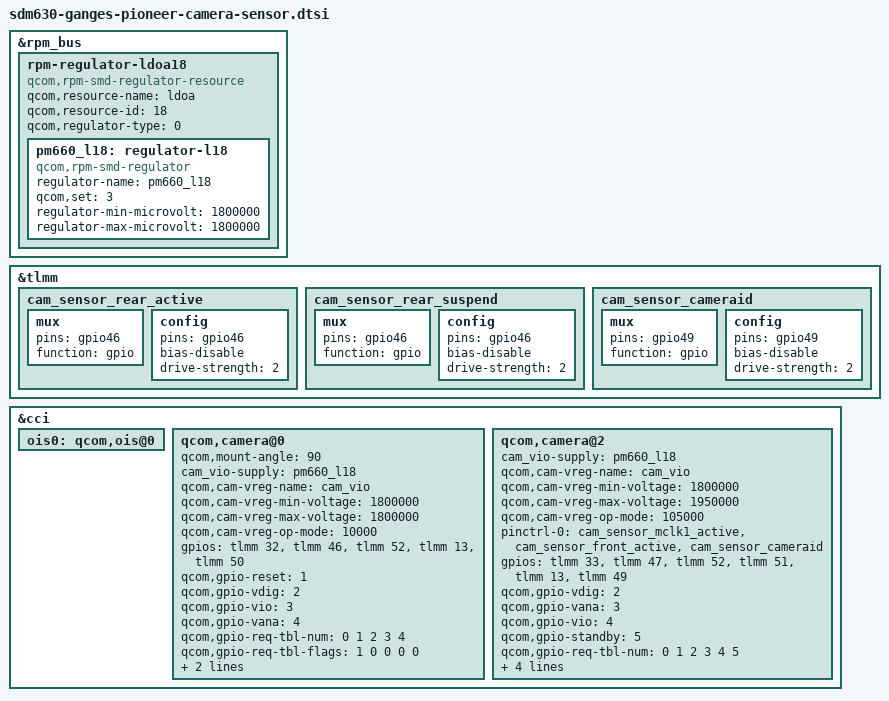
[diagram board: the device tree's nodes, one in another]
&rpm_bus {
	rpm-regulator-ldoa18 {
		compatible = "qcom,rpm-smd-regulator-resource";
		qcom,resource-name = "ldoa";
		qcom,resource-id = <18>;
		qcom,regulator-type = <0>;
		status = "disabled";

		regulator-l18 {
			compatible = "qcom,rpm-smd-regulator";
			regulator-name = "pm660_l18";
			qcom,set = <3>;
			status = "disabled";
		};
	};

	rpm-regulator-ldoa18 {
		status = "okay";
		pm660_l18: regulator-l18 {
			regulator-min-microvolt = <1800000>;
			regulator-max-microvolt = <1800000>;
			status = "okay";
		};
	};
};

&tlmm {
		cam_sensor_rear_active: cam_sensor_rear_active {
			/* RESET */
			mux {
				pins = "gpio46";
				function = "gpio";
			};

			config {
				pins = "gpio46";
				bias-disable; /* No PULL */
				drive-strength = <2>; /* 2 MA */
			};
		};

		cam_sensor_rear_suspend: cam_sensor_rear_suspend {
			/* RESET */
			mux {
				pins = "gpio46";
				function = "gpio";
			};

			config {
				pins = "gpio46";
				bias-disable; /* No PULL */
				drive-strength = <2>; /* 2 MA */
			};
		};

	cam_sensor_cameraid: cam_sensor_cameraid {
		mux {
			pins = "gpio49";
			function = "gpio";
		};

		config {
			pins = "gpio49";
			bias-disable; /* No PULL */
			drive-strength = <2>; /* 2 MA */
		};
	};
};

&cci {
	ois0: qcom,ois@0 {
		/delete-property/	gpios;
		/delete-property/	qcom,gpio-vaf;
		/delete-property/	qcom,gpio-req-tbl-num;
		/delete-property/	qcom,gpio-req-tbl-flags;
		/delete-property/	qcom,gpio-req-tbl-label;
		/delete-property/	pinctrl-names;
		/delete-property/	pinctrl-0;
		/delete-property/	pinctrl-1;
	};

	qcom,camera@0 {
		qcom,mount-angle = <90>;
		/delete-property/	qcom,actuator-src;
		/delete-property/	qcom,ois-src;
		/delete-property/	qcom,eeprom-src;
		cam_vio-supply = <&pm660_l18>;
		/delete-property/	cam_vana-supply;
		/delete-property/	cam_vdig-supply;
		qcom,cam-vreg-name = "cam_vio";
		qcom,cam-vreg-min-voltage = <1800000>;
		qcom,cam-vreg-max-voltage = <1800000>;
		qcom,cam-vreg-op-mode = <10000>;
		gpios = <&tlmm 32 0>,
			<&tlmm 46 0>,
			<&tlmm 52 0>,
			<&tlmm 13 0>,
			<&tlmm 50 0>;
		qcom,gpio-reset = <1>;
		qcom,gpio-vdig = <2>;
		qcom,gpio-vio = <3>;
		qcom,gpio-vana = <4>;
		qcom,gpio-req-tbl-num = <0 1 2 3 4>;
		qcom,gpio-req-tbl-flags = <1 0 0 0 0>;
		qcom,gpio-req-tbl-label = "CAMIF_MCLK0",
					"CAM_RESET0",
					"CAM_VDIG",
					"CAM_VIO",
					"CAM_VANA";
	};

	qcom,camera@2 {
		cam_vio-supply = <&pm660_l18>;
		qcom,cam-vreg-name = "cam_vio";
		qcom,cam-vreg-min-voltage = <1800000>;
		qcom,cam-vreg-max-voltage = <1950000>;
		qcom,cam-vreg-op-mode = <105000>;
		pinctrl-0 = <&cam_sensor_mclk1_active
				 &cam_sensor_front_active
				 &cam_sensor_cameraid>;
		gpios = <&tlmm 33 0>,
			<&tlmm 47 0>,
			<&tlmm 52 0>,
			<&tlmm 51 0>,
			<&tlmm 13 0>,
			<&tlmm 49 0>;
		qcom,gpio-vdig = <2>;
		qcom,gpio-vana = <3>;
		qcom,gpio-vio = <4>;
		qcom,gpio-standby = <5>;
		qcom,gpio-req-tbl-num = <0 1 2 3 4 5>;
		qcom,gpio-req-tbl-flags = <1 0 0 0 0 1>;
		qcom,gpio-req-tbl-label = "CAMIF_MCLK1",
					"CAM_RESET1",
					"CAM_VDIG1",
					"CAM_VANA1",
					"CAM_VIO1",
					"CAM_ID";
	};
};
